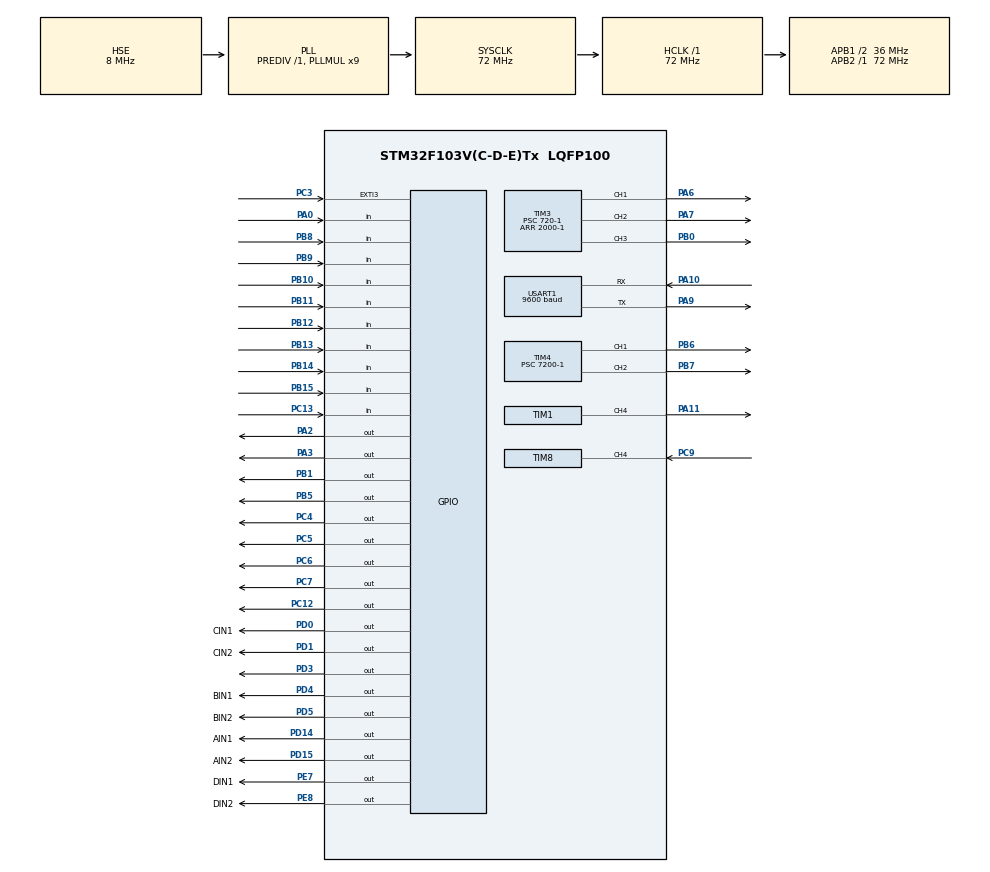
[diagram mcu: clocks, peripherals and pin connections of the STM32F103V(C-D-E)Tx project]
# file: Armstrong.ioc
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Mcu.Family=STM32F1
Mcu.Name=STM32F103V(C-D-E)Tx
Mcu.Package=LQFP100
NVIC.EXTI3_IRQn=true\:0\:0\:false\:false\:true\:true\:true\:true
NVIC.PriorityGroup=NVIC_PRIORITYGROUP_4
NVIC.TIM8_CC_IRQn=true\:0\:0\:false\:false\:true\:true\:true\:true
NVIC.USART1_IRQn=true\:0\:0\:false\:false\:true\:true\:true\:true
OSC_IN.Mode=HSE-External-Oscillator
OSC_IN.Signal=RCC_OSC_IN
OSC_OUT.Mode=HSE-External-Oscillator
OSC_OUT.Signal=RCC_OSC_OUT
PA0-WKUP.Signal=GPIO_Input
PA10.Mode=Asynchronous
PA10.Signal=USART1_RX
PA11.Signal=S_TIM1_CH4
PA13.Mode=Serial_Wire
PA13.Signal=SYS_JTMS-SWDIO
PA14.Mode=Serial_Wire
PA14.Signal=SYS_JTCK-SWCLK
PA2.GPIO_Speed=GPIO_SPEED_FREQ_HIGH
PA2.Signal=GPIO_Output
PA3.GPIO_Speed=GPIO_SPEED_FREQ_HIGH
PA3.Signal=GPIO_Output
PA6.Signal=S_TIM3_CH1
PA7.Signal=S_TIM3_CH2
PA9.Mode=Asynchronous
PA9.Signal=USART1_TX
PB0.Signal=S_TIM3_CH3
PB1.GPIO_Speed=GPIO_SPEED_FREQ_HIGH
PB1.PinState=GPIO_PIN_SET
PB1.Signal=GPIO_Output
PB10.Signal=GPIO_Input
PB11.Signal=GPIO_Input
PB12.Signal=GPIO_Input
PB13.Signal=GPIO_Input
PB14.Signal=GPIO_Input
PB15.Signal=GPIO_Input
PB5.GPIO_Speed=GPIO_SPEED_FREQ_HIGH
PB5.PinState=GPIO_PIN_SET
PB5.Signal=GPIO_Output
PB6.Signal=S_TIM4_CH1
PB7.Signal=S_TIM4_CH2
PB8.Signal=GPIO_Input
PB9.Signal=GPIO_Input
PC12.Signal=GPIO_Output
PC13-TAMPER-RTC.Signal=GPIO_Input
PC14-OSC32_IN.Mode=LSE-External-Oscillator
PC14-OSC32_IN.Signal=RCC_OSC32_IN
PC15-OSC32_OUT.Mode=LSE-External-Oscillator
PC15-OSC32_OUT.Signal=RCC_OSC32_OUT
PC3.GPIO_ModeDefaultEXTI=GPIO_MODE_IT_FALLING
PC3.Signal=GPXTI3
PC4.GPIO_Speed=GPIO_SPEED_FREQ_HIGH
PC4.Signal=GPIO_Output
PC5.GPIO_Speed=GPIO_SPEED_FREQ_HIGH
PC5.Signal=GPIO_Output
PC6.GPIO_Speed=GPIO_SPEED_FREQ_HIGH
PC6.Signal=GPIO_Output
PC7.GPIO_Speed=GPIO_SPEED_FREQ_HIGH
PC7.Signal=GPIO_Output
PC9.Signal=S_TIM8_CH4
PD0.GPIO_Label=CIN1
PD0.GPIO_Speed=GPIO_SPEED_FREQ_HIGH
PD0.Signal=GPIO_Output
PD1.GPIO_Label=CIN2
PD1.GPIO_Speed=GPIO_SPEED_FREQ_HIGH
PD1.Signal=GPIO_Output
PD14.GPIO_Label=AIN1
PD14.GPIO_Speed=GPIO_SPEED_FREQ_HIGH
PD14.Signal=GPIO_Output
PD15.GPIO_Label=AIN2
PD15.GPIO_Speed=GPIO_SPEED_FREQ_HIGH
PD15.Signal=GPIO_Output
PD3.GPIO_Speed=GPIO_SPEED_FREQ_HIGH
PD3.Signal=GPIO_Output
PD4.GPIO_Label=BIN1
PD4.GPIO_Speed=GPIO_SPEED_FREQ_HIGH
PD4.Signal=GPIO_Output
PD5.GPIO_Label=BIN2
PD5.GPIO_Speed=GPIO_SPEED_FREQ_HIGH
PD5.Signal=GPIO_Output
PE7.GPIO_Label=DIN1
PE7.GPIO_Speed=GPIO_SPEED_FREQ_HIGH
PE7.Signal=GPIO_Output
PE8.GPIO_Label=DIN2
PE8.GPIO_Speed=GPIO_SPEED_FREQ_HIGH
PE8.Signal=GPIO_Output
ProjectManager.HeapSize=0x200
ProjectManager.StackSize=0x400
ProjectManager.TargetToolchain=STM32CubeIDE
RCC.AHBFreq_Value=72000000
RCC.APB1CLKDivider=RCC_HCLK_DIV2
RCC.APB1Freq_Value=36000000
RCC.APB1TimFreq_Value=72000000
RCC.APB2Freq_Value=72000000
RCC.APB2TimFreq_Value=72000000
RCC.HCLKFreq_Value=72000000
RCC.PLLMUL=RCC_PLL_MUL9
RCC.PLLSourceVirtual=RCC_PLLSOURCE_HSE
RCC.SYSCLKFreq_VALUE=72000000
RCC.SYSCLKSource=RCC_SYSCLKSOURCE_PLLCLK
RCC.USBFreq_Value=72000000
SH.S_TIM1_CH4.0=TIM1_CH4,PWM Generation4 CH4
SH.S_TIM3_CH1.0=TIM3_CH1,PWM Generation1 CH1
SH.S_TIM3_CH2.0=TIM3_CH2,PWM Generation2 CH2
SH.S_TIM3_CH3.0=TIM3_CH3,PWM Generation3 CH3
SH.S_TIM4_CH1.0=TIM4_CH1,PWM Generation1 CH1
SH.S_TIM4_CH2.0=TIM4_CH2,PWM Generation2 CH2
SH.S_TIM8_CH4.0=TIM8_CH4,Input_Capture4_from_TI4
TIM1.Channel-PWM\ Generation4\ CH4=TIM_CHANNEL_4
TIM1.Period=999
TIM1.Prescaler=2
TIM1.Pulse-PWM\ Generation4\ CH4=299
TIM3.Channel-PWM\ Generation1\ CH1=TIM_CHANNEL_1
TIM3.Channel-PWM\ Generation2\ CH2=TIM_CHANNEL_2
TIM3.Channel-PWM\ Generation3\ CH3=TIM_CHANNEL_3
TIM3.Period=2000-1
TIM3.Prescaler=720-1
TIM3.Pulse-PWM\ Generation1\ CH1=150
TIM3.Pulse-PWM\ Generation2\ CH2=250
TIM3.Pulse-PWM\ Generation3\ CH3=50
TIM4.Channel-PWM\ Generation1\ CH1=TIM_CHANNEL_1
TIM4.Channel-PWM\ Generation2\ CH2=TIM_CHANNEL_2
TIM4.Period=200-1
TIM4.Prescaler=7200-1
TIM4.Pulse-PWM\ Generation1\ CH1=15
TIM4.Pulse-PWM\ Generation2\ CH2=8
TIM8.Channel-Input_Capture4_from_TI4=TIM_CHANNEL_4
TIM8.Prescaler=72-1
USART1.BaudRate=9600
USART1.VirtualMode=VM_ASYNC
VP_TIM1_VS_ClockSourceINT.Mode=Internal
VP_TIM3_VS_ClockSourceINT.Mode=Internal
VP_TIM4_VS_ClockSourceINT.Mode=Internal
board=custom

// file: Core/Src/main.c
#include "main.h"
#include "bsp_ov7725.h"
#include "bsp_sccb.h"
 TIM_HandleTypeDef htim1;
TIM_HandleTypeDef htim3;
TIM_HandleTypeDef htim4;
TIM_HandleTypeDef htim8;

UART_HandleTypeDef huart1;

void SystemClock_Config(void);
static void MX_GPIO_Init(void);
static void MX_USART1_UART_Init(void);
static void MX_TIM3_Init(void);
static void MX_TIM4_Init(void);
static void MX_TIM1_Init(void);
static void MX_TIM8_Init(void);

volatile uint8_t Ov7725_vsync;

uint8_t Rxstr;
void gradual_change_PWM(TIM_HandleTypeDef* htim, uint32_t channel, uint16_t current, uint16_t new, uint8_t step)
{
	uint16_t temp = current;
	uint16_t difference = current - new;
	while(temp-new != 0) {
		if(difference > 0) { //decrease to new
			if(temp - new > step) {
				__HAL_TIM_SET_COMPARE(htim, channel, temp-step);
				HAL_Delay(100);
				temp -= step;
			} else {
				__HAL_TIM_SET_COMPARE(htim, channel, new);
				HAL_Delay(100);
				temp = new;
			}
		} else if(difference < 0) { //increase to new
			if(new - temp > step) {
				__HAL_TIM_SET_COMPARE(htim, channel, temp+step);
				HAL_Delay(100);
				temp += step;
			} else {
				__HAL_TIM_SET_COMPARE(htim, channel, new);
				HAL_Delay(100);
				temp = new;
			}
		}
	}
}

void ARM_StandByPosition()
{
//	uint16_t current_tim3_ch3 = __HAL_TIM_GET_COMPARE(&htim3, TIM_CHANNEL_3);

	//gradual_change_PWM(&htim3, TIM_CHANNEL_3, current_tim3_ch3, 50, 10);
	__HAL_TIM_SET_COMPARE(&htim3, TIM_CHANNEL_3, 50);
	HAL_Delay(500);
	__HAL_TIM_SET_COMPARE(&htim3, TIM_CHANNEL_1, 150);
	__HAL_TIM_SET_COMPARE(&htim3, TIM_CHANNEL_2, 250);
	__HAL_TIM_SET_COMPARE(&htim4, TIM_CHANNEL_1, 15);
	__HAL_TIM_SET_COMPARE(&htim4, TIM_CHANNEL_2, 8);
	HAL_Delay(300);
}

void ARM_stretch(uint8_t distance)
{
	uint16_t current_tim3_ch1 = __HAL_TIM_GET_COMPARE(&htim3, TIM_CHANNEL_1);
	uint16_t current_tim3_ch2 = __HAL_TIM_GET_COMPARE(&htim3, TIM_CHANNEL_2);
	uint16_t current_tim4_ch2 = __HAL_TIM_GET_COMPARE(&htim4, TIM_CHANNEL_2);

	//check distance range (10-18cm)
	if(distance < 10) {
		distance = 10;
	} else if (distance > 18) {
		distance = 18;
	}

	//calculate the PWM by the distance:
	uint16_t new_tim3_ch1 = 72 + (100-72)*(18-distance)/(18-10); //arm base
	uint16_t new_tim3_ch2 = 190 + (260-190)*(18-distance)/(18-10); //arm arm
	uint16_t new_tim4_ch2 = 12 + (17-12)*(18-distance)/(18-10); //claw up down

	//stretch (varies in distance)
	__HAL_TIM_SET_COMPARE(&htim3, TIM_CHANNEL_3, 50); //confirm arm is in the front
	__HAL_TIM_SET_COMPARE(&htim4, TIM_CHANNEL_1, 17); //claw grab
	gradual_change_PWM(&htim4, TIM_CHANNEL_2, current_tim4_ch2, new_tim4_ch2, 5); //claw up down
	HAL_Delay(100);
	gradual_change_PWM(&htim3, TIM_CHANNEL_2, current_tim3_ch2, new_tim3_ch2, 5); //arm arm
	gradual_change_PWM(&htim3, TIM_CHANNEL_1, current_tim3_ch1, new_tim3_ch1, 5); //arm base
}

void ARM_prepare_to_release()
{
	//rise the arm to the position so that the ball can directly release when reach on the top of the box
	uint16_t current_tim3_ch1 = __HAL_TIM_GET_COMPARE(&htim3, TIM_CHANNEL_1);
	uint16_t current_tim3_ch2 = __HAL_TIM_GET_COMPARE(&htim3, TIM_CHANNEL_2);
//	uint16_t current_tim3_ch3 = __HAL_TIM_GET_COMPARE(&htim3, TIM_CHANNEL_3);
	uint16_t current_tim4_ch2 = __HAL_TIM_GET_COMPARE(&htim4, TIM_CHANNEL_2);

	__HAL_TIM_SET_COMPARE(&htim3, TIM_CHANNEL_1, 190); //arm base
	HAL_Delay(500);
	gradual_change_PWM(&htim3, TIM_CHANNEL_1, current_tim3_ch1, 200, 5); //arm base

	gradual_change_PWM(&htim3, TIM_CHANNEL_2, current_tim3_ch2, 240, 5); //arm arm

	gradual_change_PWM(&htim4, TIM_CHANNEL_2, current_tim4_ch2, 11, 3); //claw up down

	//rotate 180 to back
	__HAL_TIM_SET_COMPARE(&htim3, TIM_CHANNEL_3, 250); //base rotation
	HAL_Delay(500);
	//gradual_change_PWM(&htim3, TIM_CHANNEL_3, current_tim3_ch3, 250, 5); //base rotation
}

void delay (uint16_t time)
{
	__HAL_TIM_SET_COUNTER(&htim8, 0);
	while (__HAL_TIM_GET_COUNTER (&htim8) < time);
}

uint32_t IC_Val1 = 0;
uint32_t IC_Val2 = 0;
uint32_t Difference = 0;
uint8_t Is_First_Captured = 0;  // is the first value captured?
uint8_t Distance  = 0;

#define TRIG_PIN GPIO_PIN_12
#define TRIG_PORT GPIOC

void HAL_TIM_IC_CaptureCallback(TIM_HandleTypeDef *htim)
{
	if (htim->Channel == HAL_TIM_ACTIVE_CHANNEL_4)  // if the interrupt source is channel4
	{
		if (Is_First_Captured==0) // if the first value is not captured
		{
			IC_Val1 = HAL_TIM_ReadCapturedValue(htim, TIM_CHANNEL_4); // read the first value
			Is_First_Captured = 1;  // set the first captured as true
			// Now change the polarity to falling edge
			__HAL_TIM_SET_CAPTUREPOLARITY(htim, TIM_CHANNEL_4, TIM_INPUTCHANNELPOLARITY_FALLING);
		}

		else if (Is_First_Captured==1)   // if the first is already captured
		{
			IC_Val2 = HAL_TIM_ReadCapturedValue(htim, TIM_CHANNEL_4);  // read second value
			__HAL_TIM_SET_COUNTER(htim, 0);  // reset the counter

			if (IC_Val2 > IC_Val1)
			{
				Difference = IC_Val2-IC_Val1;
			}

			else if (IC_Val1 > IC_Val2)
			{
				Difference = (0xffff - IC_Val1) + IC_Val2;
			}

			Distance = Difference * .034/2;
			Is_First_Captured = 0; // set it back to false

			// set polarity to rising edge
			__HAL_TIM_SET_CAPTUREPOLARITY(htim, TIM_CHANNEL_4, TIM_INPUTCHANNELPOLARITY_RISING);
			__HAL_TIM_DISABLE_IT(&htim8, TIM_IT_CC4);
		}
	}
}

void HCSR04_Read (void)
{
	HAL_GPIO_WritePin(TRIG_PORT, TRIG_PIN, GPIO_PIN_SET);  // pull the TRIG pin HIGH
	delay(10);  // wait for 10 us
	HAL_GPIO_WritePin(TRIG_PORT, TRIG_PIN, GPIO_PIN_RESET);  // pull the TRIG pin low

	__HAL_TIM_ENABLE_IT(&htim8, TIM_IT_CC4);
}

int main(void)
{
  HAL_Init();

  SystemClock_Config();

  MX_GPIO_Init();
  MX_USART1_UART_Init();
  MX_TIM3_Init();
  MX_TIM4_Init();
  MX_TIM1_Init();
  MX_TIM8_Init();

  HAL_TIM_IC_Start_IT(&htim8, TIM_CHANNEL_4);
  HAL_GPIO_WritePin(AIN1_GPIO_Port, AIN1_Pin, GPIO_PIN_RESET);
  HAL_GPIO_WritePin(AIN2_GPIO_Port, AIN2_Pin, GPIO_PIN_RESET);
  HAL_GPIO_WritePin(BIN1_GPIO_Port, BIN1_Pin, GPIO_PIN_RESET);
  HAL_GPIO_WritePin(BIN2_GPIO_Port, BIN2_Pin, GPIO_PIN_RESET);
  HAL_GPIO_WritePin(CIN1_GPIO_Port, CIN1_Pin, GPIO_PIN_RESET);
  HAL_GPIO_WritePin(CIN2_GPIO_Port, CIN2_Pin, GPIO_PIN_RESET);
  HAL_GPIO_WritePin(DIN1_GPIO_Port, DIN1_Pin, GPIO_PIN_RESET);
  HAL_GPIO_WritePin(DIN2_GPIO_Port, DIN2_Pin, GPIO_PIN_RESET);

  ARM_StandByPosition();
  uint8_t mode = 0;
  while(1)
  {
	  if (HAL_GPIO_ReadPin(GPIOA, GPIO_PIN_0) == GPIO_PIN_SET){
		  //manual mode
		  mode = 1;
		  break;

	  }
	  else if (HAL_GPIO_ReadPin(GPIOC, GPIO_PIN_13) == GPIO_PIN_SET){
		  //auto mode
		  mode = 2;
		  break;
	  }
  }
if (mode == 1)
	{
		HAL_GPIO_WritePin(GPIOB, GPIO_PIN_1, GPIO_PIN_SET);
		HAL_GPIO_WritePin(GPIOB, GPIO_PIN_5, GPIO_PIN_RESET);
		HAL_Delay(1000);
		HAL_GPIO_WritePin(GPIOB, GPIO_PIN_5, GPIO_PIN_SET);
		HAL_Delay(1000);
		HAL_GPIO_WritePin(GPIOB, GPIO_PIN_5, GPIO_PIN_RESET);
		HAL_Delay(1000);
		HAL_GPIO_WritePin(GPIOB, GPIO_PIN_5, GPIO_PIN_SET);

	  while (1)
	  {
//			sensor testing
//			HCSR04_Read();
//			HAL_UART_Transmit(&huart1, &Distance, 1 ,100);
//			HAL_Delay(1000);
			if (HAL_UART_Receive(&huart1,&Rxstr,1,100)==HAL_OK) {
				if (Rxstr == 'R') {
					HAL_GPIO_WritePin(GPIOB, GPIO_PIN_1, GPIO_PIN_SET);
					HAL_GPIO_WritePin(GPIOB, GPIO_PIN_5, GPIO_PIN_RESET);
				}
				else if (Rxstr == 'B') {
					HAL_GPIO_WritePin(GPIOB, GPIO_PIN_5, GPIO_PIN_SET);
					HAL_GPIO_WritePin(GPIOB, GPIO_PIN_1, GPIO_PIN_RESET);
				}
				else if (Rxstr == 'W') {
					//forward movement
					//AIN1 0	1			0
					//AIN2 0	0			1
					//	  STOP  FORWARD		BACKWARD
					  HAL_GPIO_WritePin(AIN1_GPIO_Port, AIN1_Pin, GPIO_PIN_SET);
					  HAL_GPIO_WritePin(AIN2_GPIO_Port, AIN2_Pin, GPIO_PIN_RESET);
					  HAL_GPIO_WritePin(BIN1_GPIO_Port, BIN1_Pin, GPIO_PIN_SET);
					  HAL_GPIO_WritePin(BIN2_GPIO_Port, BIN2_Pin, GPIO_PIN_RESET);
					  HAL_GPIO_WritePin(CIN1_GPIO_Port, CIN1_Pin, GPIO_PIN_SET);
					  HAL_GPIO_WritePin(CIN2_GPIO_Port, CIN2_Pin, GPIO_PIN_RESET);
					  HAL_GPIO_WritePin(DIN1_GPIO_Port, DIN1_Pin, GPIO_PIN_SET);
					  HAL_GPIO_WritePin(DIN2_GPIO_Port, DIN2_Pin, GPIO_PIN_RESET);
				}
				else if (Rxstr == 'S') {
					//backward movement
					  HAL_GPIO_WritePin(AIN1_GPIO_Port, AIN1_Pin, GPIO_PIN_RESET);
					  HAL_GPIO_WritePin(AIN2_GPIO_Port, AIN2_Pin, GPIO_PIN_SET);
					  HAL_GPIO_WritePin(BIN1_GPIO_Port, BIN1_Pin, GPIO_PIN_RESET);
					  HAL_GPIO_WritePin(BIN2_GPIO_Port, BIN2_Pin, GPIO_PIN_SET);
					  HAL_GPIO_WritePin(CIN1_GPIO_Port, CIN1_Pin, GPIO_PIN_RESET);
					  HAL_GPIO_WritePin(CIN2_GPIO_Port, CIN2_Pin, GPIO_PIN_SET);
					  HAL_GPIO_WritePin(DIN1_GPIO_Port, DIN1_Pin, GPIO_PIN_RESET);
					  HAL_GPIO_WritePin(DIN2_GPIO_Port, DIN2_Pin, GPIO_PIN_SET);

				}
				else if (Rxstr == 'A') {
					//left movement
					  HAL_GPIO_WritePin(AIN1_GPIO_Port, AIN1_Pin, GPIO_PIN_SET);
					  HAL_GPIO_WritePin(AIN2_GPIO_Port, AIN2_Pin, GPIO_PIN_RESET);
					  HAL_GPIO_WritePin(BIN1_GPIO_Port, BIN1_Pin, GPIO_PIN_RESET);
					  HAL_GPIO_WritePin(BIN2_GPIO_Port, BIN2_Pin, GPIO_PIN_SET);
					  HAL_GPIO_WritePin(CIN1_GPIO_Port, CIN1_Pin, GPIO_PIN_SET);
					  HAL_GPIO_WritePin(CIN2_GPIO_Port, CIN2_Pin, GPIO_PIN_RESET);
					  HAL_GPIO_WritePin(DIN1_GPIO_Port, DIN1_Pin, GPIO_PIN_RESET);
					  HAL_GPIO_WritePin(DIN2_GPIO_Port, DIN2_Pin, GPIO_PIN_SET);
				}
				else if (Rxstr == 'D') {
					// right movement
					  HAL_GPIO_WritePin(AIN1_GPIO_Port, AIN1_Pin, GPIO_PIN_RESET);
					  HAL_GPIO_WritePin(AIN2_GPIO_Port, AIN2_Pin, GPIO_PIN_SET);
					  HAL_GPIO_WritePin(BIN1_GPIO_Port, BIN1_Pin, GPIO_PIN_SET);
					  HAL_GPIO_WritePin(BIN2_GPIO_Port, BIN2_Pin, GPIO_PIN_RESET);
					  HAL_GPIO_WritePin(CIN1_GPIO_Port, CIN1_Pin, GPIO_PIN_RESET);
					  HAL_GPIO_WritePin(CIN2_GPIO_Port, CIN2_Pin, GPIO_PIN_SET);
					  HAL_GPIO_WritePin(DIN1_GPIO_Port, DIN1_Pin, GPIO_PIN_SET);
					  HAL_GPIO_WritePin(DIN2_GPIO_Port, DIN2_Pin, GPIO_PIN_RESET);
				}
				else if (Rxstr == 'L') {
					// Counter Clock Wise
					  HAL_GPIO_WritePin(AIN1_GPIO_Port, AIN1_Pin, GPIO_PIN_SET);
					  HAL_GPIO_WritePin(AIN2_GPIO_Port, AIN2_Pin, GPIO_PIN_RESET);
					  HAL_GPIO_WritePin(BIN1_GPIO_Port, BIN1_Pin, GPIO_PIN_RESET);
					  HAL_GPIO_WritePin(BIN2_GPIO_Port, BIN2_Pin, GPIO_PIN_SET);
					  HAL_GPIO_WritePin(CIN1_GPIO_Port, CIN1_Pin, GPIO_PIN_RESET);
					  HAL_GPIO_WritePin(CIN2_GPIO_Port, CIN2_Pin, GPIO_PIN_SET);
					  HAL_GPIO_WritePin(DIN1_GPIO_Port, DIN1_Pin, GPIO_PIN_SET);
					  HAL_GPIO_WritePin(DIN2_GPIO_Port, DIN2_Pin, GPIO_PIN_RESET);
				}
				else if (Rxstr == 'K') {
					// Clock Wise
					  HAL_GPIO_WritePin(AIN1_GPIO_Port, AIN1_Pin, GPIO_PIN_RESET);
					  HAL_GPIO_WritePin(AIN2_GPIO_Port, AIN2_Pin, GPIO_PIN_SET);
					  HAL_GPIO_WritePin(BIN1_GPIO_Port, BIN1_Pin, GPIO_PIN_SET);
					  HAL_GPIO_WritePin(BIN2_GPIO_Port, BIN2_Pin, GPIO_PIN_RESET);
					  HAL_GPIO_WritePin(CIN1_GPIO_Port, CIN1_Pin, GPIO_PIN_SET);
					  HAL_GPIO_WritePin(CIN2_GPIO_Port, CIN2_Pin, GPIO_PIN_RESET);
					  HAL_GPIO_WritePin(DIN1_GPIO_Port, DIN1_Pin, GPIO_PIN_RESET);
					  HAL_GPIO_WritePin(DIN2_GPIO_Port, DIN2_Pin, GPIO_PIN_SET);
				}
				else if (Rxstr == 'Q') {
					// Clock Wise
					  HAL_GPIO_WritePin(AIN1_GPIO_Port, AIN1_Pin, GPIO_PIN_SET);
					  HAL_GPIO_WritePin(AIN2_GPIO_Port, AIN2_Pin, GPIO_PIN_RESET);
					  HAL_GPIO_WritePin(BIN1_GPIO_Port, BIN1_Pin, GPIO_PIN_RESET);
					  HAL_GPIO_WritePin(BIN2_GPIO_Port, BIN2_Pin, GPIO_PIN_RESET);
					  HAL_GPIO_WritePin(CIN1_GPIO_Port, CIN1_Pin, GPIO_PIN_SET);
					  HAL_GPIO_WritePin(CIN2_GPIO_Port, CIN2_Pin, GPIO_PIN_RESET);
					  HAL_GPIO_WritePin(DIN1_GPIO_Port, DIN1_Pin, GPIO_PIN_RESET);
					  HAL_GPIO_WritePin(DIN2_GPIO_Port, DIN2_Pin, GPIO_PIN_RESET);
				}
				else if (Rxstr == 'E') {
					// Clock Wise
					  HAL_GPIO_WritePin(AIN1_GPIO_Port, AIN1_Pin, GPIO_PIN_RESET);
					  HAL_GPIO_WritePin(AIN2_GPIO_Port, AIN2_Pin, GPIO_PIN_RESET);
					  HAL_GPIO_WritePin(BIN1_GPIO_Port, BIN1_Pin, GPIO_PIN_SET);
					  HAL_GPIO_WritePin(BIN2_GPIO_Port, BIN2_Pin, GPIO_PIN_RESET);
					  HAL_GPIO_WritePin(CIN1_GPIO_Port, CIN1_Pin, GPIO_PIN_RESET);
					  HAL_GPIO_WritePin(CIN2_GPIO_Port, CIN2_Pin, GPIO_PIN_RESET);
					  HAL_GPIO_WritePin(DIN1_GPIO_Port, DIN1_Pin, GPIO_PIN_SET);
					  HAL_GPIO_WritePin(DIN2_GPIO_Port, DIN2_Pin, GPIO_PIN_RESET);
				}
				else if (Rxstr == 'F') {
					// Clock Wise
					  HAL_GPIO_WritePin(AIN1_GPIO_Port, AIN1_Pin, GPIO_PIN_RESET);
					  HAL_GPIO_WritePin(AIN2_GPIO_Port, AIN2_Pin, GPIO_PIN_RESET);
					  HAL_GPIO_WritePin(BIN1_GPIO_Port, BIN1_Pin, GPIO_PIN_RESET);
					  HAL_GPIO_WritePin(BIN2_GPIO_Port, BIN2_Pin, GPIO_PIN_SET);
					  HAL_GPIO_WritePin(CIN1_GPIO_Port, CIN1_Pin, GPIO_PIN_RESET);
					  HAL_GPIO_WritePin(CIN2_GPIO_Port, CIN2_Pin, GPIO_PIN_RESET);
					  HAL_GPIO_WritePin(DIN1_GPIO_Port, DIN1_Pin, GPIO_PIN_RESET);
					  HAL_GPIO_WritePin(DIN2_GPIO_Port, DIN2_Pin, GPIO_PIN_SET);
				}
				else if (Rxstr == 'G') {
					// Clock Wise
					  HAL_GPIO_WritePin(AIN1_GPIO_Port, AIN1_Pin, GPIO_PIN_RESET);
					  HAL_GPIO_WritePin(AIN2_GPIO_Port, AIN2_Pin, GPIO_PIN_SET);
					  HAL_GPIO_WritePin(BIN1_GPIO_Port, BIN1_Pin, GPIO_PIN_RESET);
					  HAL_GPIO_WritePin(BIN2_GPIO_Port, BIN2_Pin, GPIO_PIN_RESET);
					  HAL_GPIO_WritePin(CIN1_GPIO_Port, CIN1_Pin, GPIO_PIN_RESET);
					  HAL_GPIO_WritePin(CIN2_GPIO_Port, CIN2_Pin, GPIO_PIN_SET);
					  HAL_GPIO_WritePin(DIN1_GPIO_Port, DIN1_Pin, GPIO_PIN_RESET);
					  HAL_GPIO_WritePin(DIN2_GPIO_Port, DIN2_Pin, GPIO_PIN_RESET);
				}
				else if (Rxstr == 'P') {
					// pause the car
					  HAL_GPIO_WritePin(AIN1_GPIO_Port, AIN1_Pin, GPIO_PIN_RESET);
					  HAL_GPIO_WritePin(AIN2_GPIO_Port, AIN2_Pin, GPIO_PIN_RESET);
					  HAL_GPIO_WritePin(BIN1_GPIO_Port, BIN1_Pin, GPIO_PIN_RESET);
					  HAL_GPIO_WritePin(BIN2_GPIO_Port, BIN2_Pin, GPIO_PIN_RESET);
					  HAL_GPIO_WritePin(CIN1_GPIO_Port, CIN1_Pin, GPIO_PIN_RESET);
					  HAL_GPIO_WritePin(CIN2_GPIO_Port, CIN2_Pin, GPIO_PIN_RESET);
					  HAL_GPIO_WritePin(DIN1_GPIO_Port, DIN1_Pin, GPIO_PIN_RESET);
					  HAL_GPIO_WritePin(DIN2_GPIO_Port, DIN2_Pin, GPIO_PIN_RESET);
				}
				else if (Rxstr == 'Z'){
					//adjust the arm, prepare to grab the ball
					uint8_t distance = 10;
					//first find the distance of the ball

					//!!!!!test ultrasonic sensor only, plz replace it to distance find by circle detection
//					HCSR04_Read();
//					distance = Distance;
//					HAL_UART_Transmit(&huart1, &distance, 1 ,100);

					//go to arm position
					ARM_stretch(distance);
				}
				else if (Rxstr == 'X') {
					//grab the ball
					__HAL_TIM_SET_COMPARE(&htim4, TIM_CHANNEL_1, 10);
				}
				else if (Rxstr == 'C') {
					//prepare the release
					ARM_prepare_to_release();
				}
				else if (Rxstr == 'V') {
					//release the ball and return to standby position
					__HAL_TIM_SET_COMPARE(&htim4, TIM_CHANNEL_1, 17);
					HAL_Delay(500);
					ARM_StandByPosition();
				}
				else if (Rxstr == 'N') {
					//standby
					ARM_StandByPosition();
				}
			}
		}
	}
else if (mode == 2)
	{
		uint8_t temp_d = 0;
	  while(Ov7725_Init() != SUCCESS){};
	  	Ov7725_vsync = 0;
	//	  if (Ov7725_vsync == 2)
	//	  {
	//		  FIFO_PREPARE;
	//		  ImagDisp();
	//		  Ov7725_vsync = 0;
	//	  }
		HAL_GPIO_WritePin(GPIOB, GPIO_PIN_5, GPIO_PIN_SET);
		HAL_GPIO_WritePin(GPIOB, GPIO_PIN_1, GPIO_PIN_RESET);
		HAL_Delay(1000);
		HAL_GPIO_WritePin(GPIOB, GPIO_PIN_1, GPIO_PIN_SET);
		HAL_Delay(1000);
		HAL_GPIO_WritePin(GPIOB, GPIO_PIN_1, GPIO_PIN_RESET);
		HAL_Delay(1000);
		HAL_GPIO_WritePin(GPIOB, GPIO_PIN_1, GPIO_PIN_SET);
		while(1)
		{
			//check the distance before moving forward
			HCSR04_Read();
			HAL_Delay(500);
			if (Distance <30)
			{
				// right movement
				HAL_GPIO_WritePin(AIN1_GPIO_Port, AIN1_Pin, GPIO_PIN_RESET);
				HAL_GPIO_WritePin(AIN2_GPIO_Port, AIN2_Pin, GPIO_PIN_SET);
				HAL_GPIO_WritePin(BIN1_GPIO_Port, BIN1_Pin, GPIO_PIN_SET);
				HAL_GPIO_WritePin(BIN2_GPIO_Port, BIN2_Pin, GPIO_PIN_RESET);
				HAL_GPIO_WritePin(CIN1_GPIO_Port, CIN1_Pin, GPIO_PIN_RESET);
				HAL_GPIO_WritePin(CIN2_GPIO_Port, CIN2_Pin, GPIO_PIN_SET);
				HAL_GPIO_WritePin(DIN1_GPIO_Port, DIN1_Pin, GPIO_PIN_SET);
				HAL_GPIO_WritePin(DIN2_GPIO_Port, DIN2_Pin, GPIO_PIN_RESET);
				HAL_Delay(1000);
				// Counter Clock Wise for 180 degrees
				HAL_GPIO_WritePin(AIN1_GPIO_Port, AIN1_Pin, GPIO_PIN_SET);
				HAL_GPIO_WritePin(AIN2_GPIO_Port, AIN2_Pin, GPIO_PIN_RESET);
				HAL_GPIO_WritePin(BIN1_GPIO_Port, BIN1_Pin, GPIO_PIN_RESET);
				HAL_GPIO_WritePin(BIN2_GPIO_Port, BIN2_Pin, GPIO_PIN_SET);
				HAL_GPIO_WritePin(CIN1_GPIO_Port, CIN1_Pin, GPIO_PIN_RESET);
				HAL_GPIO_WritePin(CIN2_GPIO_Port, CIN2_Pin, GPIO_PIN_SET);
				HAL_GPIO_WritePin(DIN1_GPIO_Port, DIN1_Pin, GPIO_PIN_SET);
				HAL_GPIO_WritePin(DIN2_GPIO_Port, DIN2_Pin, GPIO_PIN_RESET);
				HAL_Delay(2500/2);
				continue;
			}
			//forward for 0.5 second
			  HAL_GPIO_WritePin(AIN1_GPIO_Port, AIN1_Pin, GPIO_PIN_SET);
			  HAL_GPIO_WritePin(AIN2_GPIO_Port, AIN2_Pin, GPIO_PIN_RESET);
			  HAL_GPIO_WritePin(BIN1_GPIO_Port, BIN1_Pin, GPIO_PIN_SET);
			  HAL_GPIO_WritePin(BIN2_GPIO_Port, BIN2_Pin, GPIO_PIN_RESET);
			  HAL_GPIO_WritePin(CIN1_GPIO_Port, CIN1_Pin, GPIO_PIN_SET);
			  HAL_GPIO_WritePin(CIN2_GPIO_Port, CIN2_Pin, GPIO_PIN_RESET);
			  HAL_GPIO_WritePin(DIN1_GPIO_Port, DIN1_Pin, GPIO_PIN_SET);
			  HAL_GPIO_WritePin(DIN2_GPIO_Port, DIN2_Pin, GPIO_PIN_RESET);
			  HAL_Delay(500);
			  //pause
			  HAL_GPIO_WritePin(AIN1_GPIO_Port, AIN1_Pin, GPIO_PIN_RESET);
			  HAL_GPIO_WritePin(AIN2_GPIO_Port, AIN2_Pin, GPIO_PIN_RESET);
			  HAL_GPIO_WritePin(BIN1_GPIO_Port, BIN1_Pin, GPIO_PIN_RESET);
			  HAL_GPIO_WritePin(BIN2_GPIO_Port, BIN2_Pin, GPIO_PIN_RESET);
			  HAL_GPIO_WritePin(CIN1_GPIO_Port, CIN1_Pin, GPIO_PIN_RESET);
			  HAL_GPIO_WritePin(CIN2_GPIO_Port, CIN2_Pin, GPIO_PIN_RESET);
			  HAL_GPIO_WritePin(DIN1_GPIO_Port, DIN1_Pin, GPIO_PIN_RESET);
			  HAL_GPIO_WritePin(DIN2_GPIO_Port, DIN2_Pin, GPIO_PIN_RESET);
			  //detection the circle around
			  for (uint8_t temp = 0; temp < 20; temp ++){
				  // Counter Clock Wise
				  HAL_GPIO_WritePin(AIN1_GPIO_Port, AIN1_Pin, GPIO_PIN_SET);
				  HAL_GPIO_WritePin(AIN2_GPIO_Port, AIN2_Pin, GPIO_PIN_RESET);
				  HAL_GPIO_WritePin(BIN1_GPIO_Port, BIN1_Pin, GPIO_PIN_RESET);
				  HAL_GPIO_WritePin(BIN2_GPIO_Port, BIN2_Pin, GPIO_PIN_SET);
				  HAL_GPIO_WritePin(CIN1_GPIO_Port, CIN1_Pin, GPIO_PIN_RESET);
				  HAL_GPIO_WritePin(CIN2_GPIO_Port, CIN2_Pin, GPIO_PIN_SET);
				  HAL_GPIO_WritePin(DIN1_GPIO_Port, DIN1_Pin, GPIO_PIN_SET);
				  HAL_GPIO_WritePin(DIN2_GPIO_Port, DIN2_Pin, GPIO_PIN_RESET);
				  // pause and detect
				  HAL_Delay(3500/20);
				  HAL_GPIO_WritePin(AIN1_GPIO_Port, AIN1_Pin, GPIO_PIN_RESET);
				  HAL_GPIO_WritePin(AIN2_GPIO_Port, AIN2_Pin, GPIO_PIN_RESET);
				  HAL_GPIO_WritePin(BIN1_GPIO_Port, BIN1_Pin, GPIO_PIN_RESET);
				  HAL_GPIO_WritePin(BIN2_GPIO_Port, BIN2_Pin, GPIO_PIN_RESET);
				  HAL_GPIO_WritePin(CIN1_GPIO_Port, CIN1_Pin, GPIO_PIN_RESET);
				  HAL_GPIO_WritePin(CIN2_GPIO_Port, CIN2_Pin, GPIO_PIN_RESET);
				  HAL_GPIO_WritePin(DIN1_GPIO_Port, DIN1_Pin, GPIO_PIN_RESET);
				  HAL_GPIO_WritePin(DIN2_GPIO_Port, DIN2_Pin, GPIO_PIN_RESET);
				  if (Ov7725_vsync == 2)
					  {
						  FIFO_PREPARE;
						  temp_d = ImagDisp();
						  if (temp_d != 0)
						  {
							  HAL_GPIO_WritePin(GPIOB, GPIO_PIN_5, GPIO_PIN_SET);
							  HAL_GPIO_WritePin(GPIOB, GPIO_PIN_1, GPIO_PIN_RESET);
							  ARM_stretch(temp_d);
							  HAL_Delay(3000);
							  __HAL_TIM_SET_COMPARE(&htim4, TIM_CHANNEL_1, 10);
							  HAL_Delay(2000);
							  ARM_prepare_to_release();
							  HAL_Delay(2000);
							  __HAL_TIM_SET_COMPARE(&htim4, TIM_CHANNEL_1, 17);
							  HAL_Delay(1000);
							  ARM_StandByPosition();

						  }
						  HAL_GPIO_WritePin(GPIOB, GPIO_PIN_5, GPIO_PIN_SET);
						  HAL_GPIO_WritePin(GPIOB, GPIO_PIN_1, GPIO_PIN_SET);
						  Ov7725_vsync = 0;
					  }
			  }
		}
	}
else
	{
		//error
		HAL_GPIO_WritePin(GPIOB, GPIO_PIN_5, GPIO_PIN_RESET);
		HAL_GPIO_WritePin(GPIOB, GPIO_PIN_1, GPIO_PIN_RESET);
		while(1)
		{

		}
	}
}

void SystemClock_Config(void)
{
  RCC_OscInitTypeDef RCC_OscInitStruct = {0};
  RCC_ClkInitTypeDef RCC_ClkInitStruct = {0};

  RCC_OscInitStruct.OscillatorType = RCC_OSCILLATORTYPE_HSE;
  RCC_OscInitStruct.HSEState = RCC_HSE_ON;
  RCC_OscInitStruct.HSEPredivValue = RCC_HSE_PREDIV_DIV1;
  RCC_OscInitStruct.HSIState = RCC_HSI_ON;
  RCC_OscInitStruct.PLL.PLLState = RCC_PLL_ON;
  RCC_OscInitStruct.PLL.PLLSource = RCC_PLLSOURCE_HSE;
  RCC_OscInitStruct.PLL.PLLMUL = RCC_PLL_MUL9;
  if (HAL_RCC_OscConfig(&RCC_OscInitStruct) != HAL_OK)
  {
    Error_Handler();
  }

  /** Initializes the CPU, AHB and APB buses clocks
  */
  RCC_ClkInitStruct.ClockType = RCC_CLOCKTYPE_HCLK|RCC_CLOCKTYPE_SYSCLK
                              |RCC_CLOCKTYPE_PCLK1|RCC_CLOCKTYPE_PCLK2;
  RCC_ClkInitStruct.SYSCLKSource = RCC_SYSCLKSOURCE_PLLCLK;
  RCC_ClkInitStruct.AHBCLKDivider = RCC_SYSCLK_DIV1;
  RCC_ClkInitStruct.APB1CLKDivider = RCC_HCLK_DIV2;
  RCC_ClkInitStruct.APB2CLKDivider = RCC_HCLK_DIV1;

  if (HAL_RCC_ClockConfig(&RCC_ClkInitStruct, FLASH_LATENCY_2) != HAL_OK)
  {
    Error_Handler();
  }
}

static void MX_TIM1_Init(void)
{

  TIM_ClockConfigTypeDef sClockSourceConfig = {0};
  TIM_MasterConfigTypeDef sMasterConfig = {0};
  TIM_OC_InitTypeDef sConfigOC = {0};
  TIM_BreakDeadTimeConfigTypeDef sBreakDeadTimeConfig = {0};

  htim1.Instance = TIM1;
  htim1.Init.Prescaler = 2;
  htim1.Init.CounterMode = TIM_COUNTERMODE_UP;
  htim1.Init.Period = 999;
  htim1.Init.ClockDivision = TIM_CLOCKDIVISION_DIV1;
  htim1.Init.RepetitionCounter = 0;
  htim1.Init.AutoReloadPreload = TIM_AUTORELOAD_PRELOAD_DISABLE;
  if (HAL_TIM_Base_Init(&htim1) != HAL_OK)
  {
    Error_Handler();
  }
  sClockSourceConfig.ClockSource = TIM_CLOCKSOURCE_INTERNAL;
  if (HAL_TIM_ConfigClockSource(&htim1, &sClockSourceConfig) != HAL_OK)
  {
    Error_Handler();
  }
  if (HAL_TIM_PWM_Init(&htim1) != HAL_OK)
  {
    Error_Handler();
  }
  sMasterConfig.MasterOutputTrigger = TIM_TRGO_RESET;
  sMasterConfig.MasterSlaveMode = TIM_MASTERSLAVEMODE_DISABLE;
  if (HAL_TIMEx_MasterConfigSynchronization(&htim1, &sMasterConfig) != HAL_OK)
  {
    Error_Handler();
  }
  sConfigOC.OCMode = TIM_OCMODE_PWM1;
  sConfigOC.Pulse = 299;
  sConfigOC.OCPolarity = TIM_OCPOLARITY_HIGH;
  sConfigOC.OCFastMode = TIM_OCFAST_DISABLE;
  sConfigOC.OCIdleState = TIM_OCIDLESTATE_RESET;
  sConfigOC.OCNIdleState = TIM_OCNIDLESTATE_RESET;
  if (HAL_TIM_PWM_ConfigChannel(&htim1, &sConfigOC, TIM_CHANNEL_4) != HAL_OK)
  {
    Error_Handler();
  }
  sBreakDeadTimeConfig.OffStateRunMode = TIM_OSSR_DISABLE;
  sBreakDeadTimeConfig.OffStateIDLEMode = TIM_OSSI_DISABLE;
  sBreakDeadTimeConfig.LockLevel = TIM_LOCKLEVEL_OFF;
  sBreakDeadTimeConfig.DeadTime = 0;
  sBreakDeadTimeConfig.BreakState = TIM_BREAK_DISABLE;
  sBreakDeadTimeConfig.BreakPolarity = TIM_BREAKPOLARITY_HIGH;
  sBreakDeadTimeConfig.AutomaticOutput = TIM_AUTOMATICOUTPUT_DISABLE;
  if (HAL_TIMEx_ConfigBreakDeadTime(&htim1, &sBreakDeadTimeConfig) != HAL_OK)
  {
    Error_Handler();
  }
  /* USER CODE BEGIN TIM1_Init 2 */
  HAL_TIM_PWM_Start(&htim1,TIM_CHANNEL_4);
  /* USER CODE END TIM1_Init 2 */
  HAL_TIM_MspPostInit(&htim1);

}

static void MX_TIM3_Init(void)
{

  TIM_ClockConfigTypeDef sClockSourceConfig = {0};
  TIM_MasterConfigTypeDef sMasterConfig = {0};
  TIM_OC_InitTypeDef sConfigOC = {0};

  htim3.Instance = TIM3;
  htim3.Init.Prescaler = 720-1;
  htim3.Init.CounterMode = TIM_COUNTERMODE_UP;
  htim3.Init.Period = 2000-1;
  htim3.Init.ClockDivision = TIM_CLOCKDIVISION_DIV1;
  htim3.Init.AutoReloadPreload = TIM_AUTORELOAD_PRELOAD_DISABLE;
  if (HAL_TIM_Base_Init(&htim3) != HAL_OK)
  {
    Error_Handler();
  }
  sClockSourceConfig.ClockSource = TIM_CLOCKSOURCE_INTERNAL;
  if (HAL_TIM_ConfigClockSource(&htim3, &sClockSourceConfig) != HAL_OK)
  {
    Error_Handler();
  }
  if (HAL_TIM_PWM_Init(&htim3) != HAL_OK)
  {
    Error_Handler();
  }
  sMasterConfig.MasterOutputTrigger = TIM_TRGO_RESET;
  sMasterConfig.MasterSlaveMode = TIM_MASTERSLAVEMODE_DISABLE;
  if (HAL_TIMEx_MasterConfigSynchronization(&htim3, &sMasterConfig) != HAL_OK)
  {
    Error_Handler();
  }
  sConfigOC.OCMode = TIM_OCMODE_PWM1;
  sConfigOC.Pulse = 150;
  sConfigOC.OCPolarity = TIM_OCPOLARITY_HIGH;
  sConfigOC.OCFastMode = TIM_OCFAST_DISABLE;
  if (HAL_TIM_PWM_ConfigChannel(&htim3, &sConfigOC, TIM_CHANNEL_1) != HAL_OK)
  {
    Error_Handler();
  }
  sConfigOC.Pulse = 250;
  if (HAL_TIM_PWM_ConfigChannel(&htim3, &sConfigOC, TIM_CHANNEL_2) != HAL_OK)
  {
    Error_Handler();
  }
  sConfigOC.Pulse = 50;
  if (HAL_TIM_PWM_ConfigChannel(&htim3, &sConfigOC, TIM_CHANNEL_3) != HAL_OK)
  {
    Error_Handler();
  }
  /* USER CODE BEGIN TIM3_Init 2 */
  HAL_TIM_PWM_Start(&htim3, TIM_CHANNEL_1);
  HAL_TIM_PWM_Start(&htim3, TIM_CHANNEL_2);
  HAL_TIM_PWM_Start(&htim3, TIM_CHANNEL_3);
  /* USER CODE END TIM3_Init 2 */
  HAL_TIM_MspPostInit(&htim3);

}

static void MX_TIM4_Init(void)
{

  TIM_ClockConfigTypeDef sClockSourceConfig = {0};
  TIM_MasterConfigTypeDef sMasterConfig = {0};
  TIM_OC_InitTypeDef sConfigOC = {0};

  htim4.Instance = TIM4;
  htim4.Init.Prescaler = 7200-1;
  htim4.Init.CounterMode = TIM_COUNTERMODE_UP;
  htim4.Init.Period = 200-1;
  htim4.Init.ClockDivision = TIM_CLOCKDIVISION_DIV1;
  htim4.Init.AutoReloadPreload = TIM_AUTORELOAD_PRELOAD_DISABLE;
  if (HAL_TIM_Base_Init(&htim4) != HAL_OK)
  {
    Error_Handler();
  }
  sClockSourceConfig.ClockSource = TIM_CLOCKSOURCE_INTERNAL;
  if (HAL_TIM_ConfigClockSource(&htim4, &sClockSourceConfig) != HAL_OK)
  {
    Error_Handler();
  }
  if (HAL_TIM_PWM_Init(&htim4) != HAL_OK)
  {
    Error_Handler();
  }
  sMasterConfig.MasterOutputTrigger = TIM_TRGO_RESET;
  sMasterConfig.MasterSlaveMode = TIM_MASTERSLAVEMODE_DISABLE;
  if (HAL_TIMEx_MasterConfigSynchronization(&htim4, &sMasterConfig) != HAL_OK)
  {
    Error_Handler();
  }
  sConfigOC.OCMode = TIM_OCMODE_PWM1;
  sConfigOC.Pulse = 15;
  sConfigOC.OCPolarity = TIM_OCPOLARITY_HIGH;
  sConfigOC.OCFastMode = TIM_OCFAST_DISABLE;
  if (HAL_TIM_PWM_ConfigChannel(&htim4, &sConfigOC, TIM_CHANNEL_1) != HAL_OK)
  {
    Error_Handler();
  }
  sConfigOC.Pulse = 8;
  if (HAL_TIM_PWM_ConfigChannel(&htim4, &sConfigOC, TIM_CHANNEL_2) != HAL_OK)
  {
    Error_Handler();
  }
  /* USER CODE BEGIN TIM4_Init 2 */
  HAL_TIM_PWM_Start(&htim4, TIM_CHANNEL_1);
  HAL_TIM_PWM_Start(&htim4, TIM_CHANNEL_2);
  /* USER CODE END TIM4_Init 2 */
  HAL_TIM_MspPostInit(&htim4);

}

static void MX_TIM8_Init(void)
{

  TIM_MasterConfigTypeDef sMasterConfig = {0};
  TIM_IC_InitTypeDef sConfigIC = {0};

  htim8.Instance = TIM8;
  htim8.Init.Prescaler = 72-1;
  htim8.Init.CounterMode = TIM_COUNTERMODE_UP;
  htim8.Init.Period = 65535;
  htim8.Init.ClockDivision = TIM_CLOCKDIVISION_DIV1;
  htim8.Init.RepetitionCounter = 0;
  htim8.Init.AutoReloadPreload = TIM_AUTORELOAD_PRELOAD_DISABLE;
  if (HAL_TIM_IC_Init(&htim8) != HAL_OK)
  {
    Error_Handler();
  }
  sMasterConfig.MasterOutputTrigger = TIM_TRGO_RESET;
  sMasterConfig.MasterSlaveMode = TIM_MASTERSLAVEMODE_DISABLE;
  if (HAL_TIMEx_MasterConfigSynchronization(&htim8, &sMasterConfig) != HAL_OK)
  {
    Error_Handler();
  }
  sConfigIC.ICPolarity = TIM_INPUTCHANNELPOLARITY_RISING;
  sConfigIC.ICSelection = TIM_ICSELECTION_DIRECTTI;
  sConfigIC.ICPrescaler = TIM_ICPSC_DIV1;
  sConfigIC.ICFilter = 0;
  if (HAL_TIM_IC_ConfigChannel(&htim8, &sConfigIC, TIM_CHANNEL_4) != HAL_OK)
  {
    Error_Handler();
  }
  /* USER CODE BEGIN TIM8_Init 2 */
  HAL_TIM_PWM_Start(&htim8, TIM_CHANNEL_4);
  /* USER CODE END TIM8_Init 2 */

}

static void MX_USART1_UART_Init(void)
{

  huart1.Instance = USART1;
  huart1.Init.BaudRate = 9600;
  huart1.Init.WordLength = UART_WORDLENGTH_8B;
  huart1.Init.StopBits = UART_STOPBITS_1;
  huart1.Init.Parity = UART_PARITY_NONE;
  huart1.Init.Mode = UART_MODE_TX_RX;
  huart1.Init.HwFlowCtl = UART_HWCONTROL_NONE;
  huart1.Init.OverSampling = UART_OVERSAMPLING_16;
  if (HAL_UART_Init(&huart1) != HAL_OK)
  {
    Error_Handler();
  }

}

static void MX_GPIO_Init(void)
{
  GPIO_InitTypeDef GPIO_InitStruct = {0};

  /* GPIO Ports Clock Enable */
  __HAL_RCC_GPIOC_CLK_ENABLE();
  __HAL_RCC_GPIOA_CLK_ENABLE();
  __HAL_RCC_GPIOB_CLK_ENABLE();
  __HAL_RCC_GPIOE_CLK_ENABLE();
  __HAL_RCC_GPIOD_CLK_ENABLE();

  /*Configure GPIO pin Output Level */
  HAL_GPIO_WritePin(GPIOA, GPIO_PIN_2|GPIO_PIN_3, GPIO_PIN_RESET);

  /*Configure GPIO pin Output Level */
  HAL_GPIO_WritePin(GPIOC, GPIO_PIN_4|GPIO_PIN_5|GPIO_PIN_6|GPIO_PIN_7
                          |GPIO_PIN_12, GPIO_PIN_RESET);

  /*Configure GPIO pin Output Level */
  HAL_GPIO_WritePin(GPIOB, GPIO_PIN_1|GPIO_PIN_5, GPIO_PIN_SET);

  /*Configure GPIO pin Output Level */
  HAL_GPIO_WritePin(GPIOE, DIN1_Pin|DIN2_Pin, GPIO_PIN_RESET);

  /*Configure GPIO pin Output Level */
  HAL_GPIO_WritePin(GPIOD, AIN1_Pin|AIN2_Pin|CIN1_Pin|CIN2_Pin
                          |GPIO_PIN_3|BIN1_Pin|BIN2_Pin, GPIO_PIN_RESET);

  /*Configure GPIO pin : PC13 */
  GPIO_InitStruct.Pin = GPIO_PIN_13;
  GPIO_InitStruct.Mode = GPIO_MODE_INPUT;
  GPIO_InitStruct.Pull = GPIO_NOPULL;
  HAL_GPIO_Init(GPIOC, &GPIO_InitStruct);

  /*Configure GPIO pin : PC3 */
  GPIO_InitStruct.Pin = GPIO_PIN_3;
  GPIO_InitStruct.Mode = GPIO_MODE_IT_FALLING;
  GPIO_InitStruct.Pull = GPIO_NOPULL;
  HAL_GPIO_Init(GPIOC, &GPIO_InitStruct);

  /*Configure GPIO pin : PA0 */
  GPIO_InitStruct.Pin = GPIO_PIN_0;
  GPIO_InitStruct.Mode = GPIO_MODE_INPUT;
  GPIO_InitStruct.Pull = GPIO_NOPULL;
  HAL_GPIO_Init(GPIOA, &GPIO_InitStruct);

  /*Configure GPIO pins : PA2 PA3 */
  GPIO_InitStruct.Pin = GPIO_PIN_2|GPIO_PIN_3;
  GPIO_InitStruct.Mode = GPIO_MODE_OUTPUT_PP;
  GPIO_InitStruct.Pull = GPIO_NOPULL;
  GPIO_InitStruct.Speed = GPIO_SPEED_FREQ_HIGH;
  HAL_GPIO_Init(GPIOA, &GPIO_InitStruct);

  /*Configure GPIO pins : PC4 PC5 */
  GPIO_InitStruct.Pin = GPIO_PIN_4|GPIO_PIN_5;
  GPIO_InitStruct.Mode = GPIO_MODE_OUTPUT_PP;
  GPIO_InitStruct.Pull = GPIO_NOPULL;
  GPIO_InitStruct.Speed = GPIO_SPEED_FREQ_HIGH;
  HAL_GPIO_Init(GPIOC, &GPIO_InitStruct);

  /*Configure GPIO pins : PC6 PC7 */
    GPIO_InitStruct.Pin = GPIO_PIN_6|GPIO_PIN_7;
    GPIO_InitStruct.Mode = GPIO_MODE_OUTPUT_OD;
    GPIO_InitStruct.Pull = GPIO_NOPULL;
    GPIO_InitStruct.Speed = GPIO_SPEED_FREQ_HIGH;
    HAL_GPIO_Init(GPIOC, &GPIO_InitStruct);

  /*Configure GPIO pins : PB1 PB5 */
  GPIO_InitStruct.Pin = GPIO_PIN_1|GPIO_PIN_5;
  GPIO_InitStruct.Mode = GPIO_MODE_OUTPUT_PP;
  GPIO_InitStruct.Pull = GPIO_NOPULL;
  GPIO_InitStruct.Speed = GPIO_SPEED_FREQ_HIGH;
  HAL_GPIO_Init(GPIOB, &GPIO_InitStruct);

  /*Configure GPIO pins : DIN1_Pin DIN2_Pin */
  GPIO_InitStruct.Pin = DIN1_Pin|DIN2_Pin;
  GPIO_InitStruct.Mode = GPIO_MODE_OUTPUT_PP;
  GPIO_InitStruct.Pull = GPIO_NOPULL;
  GPIO_InitStruct.Speed = GPIO_SPEED_FREQ_HIGH;
  HAL_GPIO_Init(GPIOE, &GPIO_InitStruct);

  /*Configure GPIO pins : PB10 PB11 PB12 PB13
                           PB14 PB15 PB8 PB9 */
  GPIO_InitStruct.Pin = GPIO_PIN_10|GPIO_PIN_11|GPIO_PIN_12|GPIO_PIN_13
                          |GPIO_PIN_14|GPIO_PIN_15|GPIO_PIN_8|GPIO_PIN_9;
  GPIO_InitStruct.Mode = GPIO_MODE_INPUT;
  GPIO_InitStruct.Pull = GPIO_NOPULL;
  HAL_GPIO_Init(GPIOB, &GPIO_InitStruct);

  /*Configure GPIO pins : AIN1_Pin AIN2_Pin CIN1_Pin CIN2_Pin
                           PD3 BIN1_Pin BIN2_Pin */
  GPIO_InitStruct.Pin = AIN1_Pin|AIN2_Pin|CIN1_Pin|CIN2_Pin
                          |GPIO_PIN_3|BIN1_Pin|BIN2_Pin;
  GPIO_InitStruct.Mode = GPIO_MODE_OUTPUT_PP;
  GPIO_InitStruct.Pull = GPIO_NOPULL;
  GPIO_InitStruct.Speed = GPIO_SPEED_FREQ_HIGH;
  HAL_GPIO_Init(GPIOD, &GPIO_InitStruct);

  /*Configure GPIO pin : PC12 */
  GPIO_InitStruct.Pin = GPIO_PIN_12;
  GPIO_InitStruct.Mode = GPIO_MODE_OUTPUT_PP;
  GPIO_InitStruct.Pull = GPIO_NOPULL;
  GPIO_InitStruct.Speed = GPIO_SPEED_FREQ_LOW;
  HAL_GPIO_Init(GPIOC, &GPIO_InitStruct);

  /* EXTI interrupt init*/
  HAL_NVIC_SetPriority(EXTI3_IRQn, 0, 0);
  HAL_NVIC_EnableIRQ(EXTI3_IRQn);

}

void Error_Handler(void)
{
}
